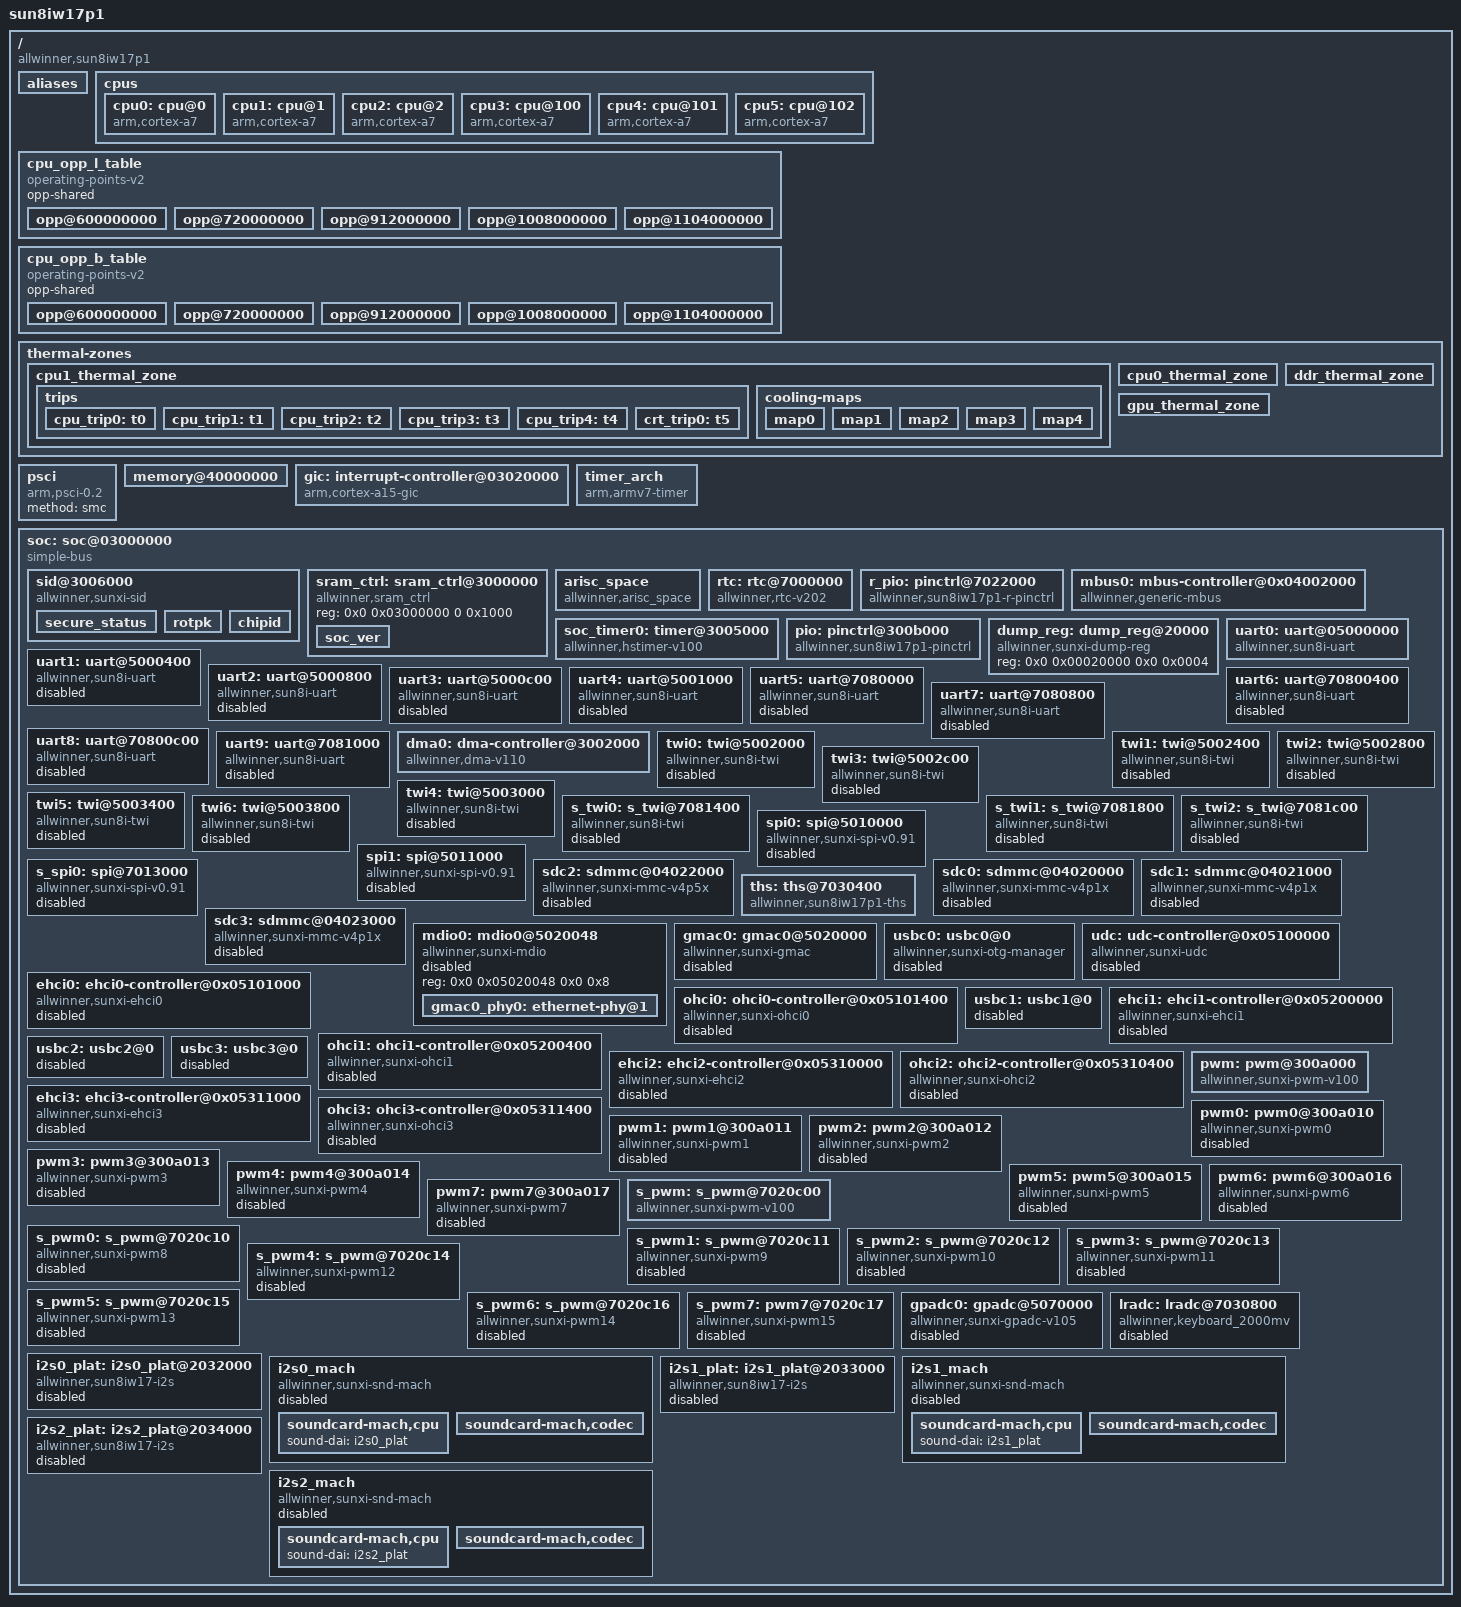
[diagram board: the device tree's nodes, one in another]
/* SPDX-License-Identifier: GPL-2.0-or-later */
/*
 * Allwinner Technology CO., Ltd. sun8iw17p1 platform
 *
 * modify base on juno.dts
 */

/* nobody use, just to "avoid"(not reslove) OOM problem at the begining of the physical memory address. */
/memreserve/ 0x40000000 0x00001000; /* reserve for out of memory access problem: size = 4K */

/* kernel used */
/memreserve/ 0x43000000 0x00000800; /* super standby range        : [0x40020000~0x41020800], size = 2K  */
/memreserve/ 0x48000000 0x01000000; /* atf                        : [0x48000000~0x49000000], size = 16M */

/* tf used */
/memreserve/ 0x48100000 0x00004000; /* arisc dram code space range: [0x48100000~0x48104000], size = 16K */
/memreserve/ 0x48104000 0x00001000; /* arisc para cfg range       : [0x48104000~0x48105000], size = 4K  */
/memreserve/ 0x48105000 0x00001000; /* arisc message pool range   : [0x48105000~0x48106000], size = 4K  */

/* pstore used */
/memreserve/ 0x48106000 0x00100000; /* ram oops log range   : [0x48106000~0x48206000], size = 1M  */
/memreserve/ 0x48200000 0x00100000; /* 360 config  size = 1M  */

#include <dt-bindings/interrupt-controller/arm-gic.h>
#include <dt-bindings/gpio/gpio.h>
#include "sun8iw17p1-clk.dtsi"
#include <dt-bindings/gpio/sun4i-gpio.h>
#include <dt-bindings/spi/sunxi-spi.h>
#include <dt-bindings/reset/sun8iw17-ccu.h>
#include <dt-bindings/reset/sun8iw17-r-ccu.h>
/ {
	model = "sun8iw17p1";
	compatible = "allwinner,sun8iw17p1";
	interrupt-parent = <&gic>;
	#address-cells = <2>;
	#size-cells = <2>;

	aliases {
		serial0 = &uart0;
		serial1 = &uart1;
		serial2 = &uart2;
		serial3 = &uart3;
		serial4 = &uart4;
		serial5 = &uart5;
		serial6 = &uart6;
		serial7 = &uart7;
		serial8 = &uart8;
		serial9 = &uart9;
		twi0 = &twi0;
		twi1 = &twi1;
		twi2 = &twi2;
		twi3 = &twi3;
		twi4 = &twi4;
		twi5 = &twi5;
		twi6 = &twi6;
		twi7 = &s_twi0;
		twi8 = &s_twi1;
		twi9 = &s_twi2;
		spi0 = &spi0;
		spi1 = &spi1;
		spi2 = &s_spi0;
		pwm0 = &pwm;
		pwm1 = &s_pwm;
		gpadc0 = &gpadc0;
	};

	cpus {
		#address-cells = <1>;
		#size-cells = <0>;

		cpu0: cpu@0 {
			device_type = "cpu";
			compatible = "arm,cortex-a7";
			reg = <0x0>;
			enable-method = "psci";
			clocks = <&clk_pll_cpu0>;
			clock-latency = <2000000>;
			clock-frequency = <1008000000>;
			operating-points-v2 = <&cpu_opp_l_table>;
			#cooling-cells = <2>;
		};

		cpu1: cpu@1 {
			device_type = "cpu";
			compatible = "arm,cortex-a7";
			reg = <0x1>;
			enable-method = "psci";
			clocks = <&clk_pll_cpu0>;
			clock-frequency = <1008000000>;
			operating-points-v2 = <&cpu_opp_l_table>;
			#cooling-cells = <2>;
		};

		cpu2: cpu@2 {
			device_type = "cpu";
			compatible = "arm,cortex-a7";
			reg = <0x2>;
			enable-method = "psci";
			clocks = <&clk_pll_cpu0>;
			clock-frequency = <1008000000>;
			operating-points-v2 = <&cpu_opp_l_table>;
			#cooling-cells = <2>;
		};

		cpu3: cpu@100 {
			device_type = "cpu";
			compatible = "arm,cortex-a7";
			reg = <0x100>;
			enable-method = "psci";
			clocks = <&clk_pll_cpu1>;
			clock-frequency = <1008000000>;
			operating-points-v2 = <&cpu_opp_b_table>;
			#cooling-cells = <2>;
		};

		cpu4: cpu@101 {
			device_type = "cpu";
			compatible = "arm,cortex-a7";
			reg = <0x101>;
			enable-method = "psci";
			clocks = <&clk_pll_cpu1>;
			clock-frequency = <1008000000>;
			operating-points-v2 = <&cpu_opp_b_table>;
			#cooling-cells = <2>;
		};

		cpu5: cpu@102 {
			device_type = "cpu";
			compatible = "arm,cortex-a7";
			reg = <0x102>;
			clocks = <&clk_pll_cpu1>;
			enable-method = "psci";
			clock-frequency = <1008000000>;
			operating-points-v2 = <&cpu_opp_b_table>;
			#cooling-cells = <2>;
		};
	};

	cpu_opp_l_table: cpu_opp_l_table {
		compatible = "operating-points-v2";
		opp-shared;

		opp@600000000 {
			opp-hz = /bits/ 64 <600000000>;
			opp-microvolt = <1060000>;
			clock-latency-ns = <2000000>;
		};

		opp@720000000 {
			opp-hz = /bits/ 64 <720000000>;
			opp-microvolt = <1060000>;
			clock-latency-ns = <2000000>;
		};

		opp@912000000 {
			opp-hz = /bits/ 64 <912000000>;
			opp-microvolt = <1200000>;
			clock-latency-ns = <2000000>;
		};

		opp@1008000000 {
			opp-hz = /bits/ 64 <1008000000>;
			opp-microvolt = <1260000>;
			clock-latency-ns = <2000000>;
		};

		opp@1104000000 {
			opp-hz = /bits/ 64 <1104000000>;
			opp-microvolt = <1300000>;
			clock-latency-ns = <2000000>;
		};
	};

	cpu_opp_b_table: cpu_opp_b_table {
		compatible = "operating-points-v2";
		opp-shared;

		opp@600000000 {
			opp-hz = /bits/ 64 <600000000>;
			opp-microvolt = <1060000>;
			clock-latency-ns = <2000000>;
		};

		opp@720000000 {
			opp-hz = /bits/ 64 <720000000>;
			opp-microvolt = <1060000>;
			clock-latency-ns = <2000000>;
		};

		opp@912000000 {
			opp-hz = /bits/ 64 <912000000>;
			opp-microvolt = <1200000>;
			clock-latency-ns = <2000000>;
		};

		opp@1008000000 {
			opp-hz = /bits/ 64 <1008000000>;
			opp-microvolt = <1260000>;
			clock-latency-ns = <2000000>;
		};

		opp@1104000000 {
			opp-hz = /bits/ 64 <1104000000>;
			opp-microvolt = <1300000>;
			clock-latency-ns = <2000000>;
		};
	};

	thermal-zones {
		cpu1_thermal_zone {
			polling-delay-passive = <1000>;
			polling-delay = <10000>;
			thermal-sensors = <&ths 0>;

			trips {
				cpu_trip0: t0 {
					temperature = <60000>;
					hysteresis = <0>;
					type = "passive";
				};

				cpu_trip1: t1 {
					temperature = <70000>;
					hysteresis = <0>;
					type = "passive";
				};

				cpu_trip2: t2 {
					temperature = <80000>;
					hysteresis = <0>;
					type = "passive";
				};

				cpu_trip3: t3 {
					temperature = <90000>;
					hysteresis = <0>;
					type = "passive";
				};

				cpu_trip4: t4 {
					temperature = <100000>;
					hysteresis = <0>;
					type = "passive";
				};

				crt_trip0: t5 {
					temperature = <120000>;
					hysteresis = <0>;
					type = "critical";
				};
			};

			cooling-maps {
				map0 {
					trip = <&cpu_trip0>;
					cooling-device = <&cpu0 1 1>,
							 <&cpu1 1 1>,
							 <&cpu2 1 1>,
							 <&cpu3 1 1>,
							 <&cpu4 1 1>,
							 <&cpu5 1 1>;
				};

				map1 {
					trip = <&cpu_trip1>;
					cooling-device = <&cpu0 2 2>,
							 <&cpu1 2 2>,
							 <&cpu2 2 2>,
							 <&cpu3 2 2>,
							 <&cpu4 2 2>,
							 <&cpu5 2 2>;
				};

				map2 {
					trip = <&cpu_trip2>;
					cooling-device = <&cpu0 3 3>,
							 <&cpu1 3 3>,
							 <&cpu2 3 3>,
							 <&cpu3 3 3>,
							 <&cpu4 3 3>,
							 <&cpu5 3 3>;
				};

				map3 {
					trip = <&cpu_trip3>;
					cooling-device = <&cpu0 4 4>,
							 <&cpu1 4 4>,
							 <&cpu2 4 4>,
							 <&cpu3 4 4>,
							 <&cpu4 4 4>,
							 <&cpu5 4 4>;
				};

				map4 {
					trip = <&cpu_trip4>;
					cooling-device = <&cpu0 5 5>,
							 <&cpu1 5 5>,
							 <&cpu2 5 5>,
							 <&cpu3 5 5>,
							 <&cpu4 5 5>,
							 <&cpu5 5 5>;
				};
			};
		};

		cpu0_thermal_zone {
			polling-delay-passive = <1000>;
			polling-delay = <10000>;
			thermal-sensors = <&ths 1>;
		};

		ddr_thermal_zone {
			polling-delay-passive = <1000>;
			polling-delay = <10000>;
			thermal-sensors = <&ths 2>;
		};

		gpu_thermal_zone {
			polling-delay-passive = <1000>;
			polling-delay = <10000>;
			thermal-sensors = <&ths 3>;
		};
	};

	psci {
		compatible = "arm,psci-0.2";
		method = "smc";
	};

	memory@40000000 {
		device_type = "memory";
		reg = <0x00000000 0x40000000 0x00000000 0x20000000>;
	};

	gic: interrupt-controller@03020000 {
		compatible = "arm,cortex-a15-gic", "arm,cortex-a9-gic";
		#interrupt-cells = <3>;
		#address-cells = <0>;
		device_type = "gic";
		interrupt-controller;
		reg = <0x0 0x03021000 0 0x1000>, /* GIC Dist */
		      <0x0 0x03022000 0 0x2000>, /* GIC CPU */
		      <0x0 0x03024000 0 0x2000>, /* GIC VCPU Control */
		      <0x0 0x03026000 0 0x2000>; /* GIC VCPU */
		interrupts = <GIC_PPI 9 0xf04>; /* GIC Maintenence IRQ */
	};

	timer_arch {
		compatible = "arm,armv7-timer";
		interrupts = <GIC_PPI 13 (GIC_CPU_MASK_SIMPLE(6) | IRQ_TYPE_LEVEL_LOW)>, /* Secure Phys IRQ */
			     <GIC_PPI 14 (GIC_CPU_MASK_SIMPLE(6) | IRQ_TYPE_LEVEL_LOW)>; /* Non-secure Phys IRQ */
		clock-frequency = <24000000>;
		arm,cpu-registers-not-fw-configured;
		arm,no-tick-in-suspend;
	};

	soc: soc@03000000 {
		compatible = "simple-bus";
		#address-cells = <2>;
		#size-cells = <2>;
		ranges;
		device_type = "soc";

		sid@3006000 {
			compatible = "allwinner,sunxi-sid";
			reg = <0x0 0x03006000 0 0x1000>;
			#address-cells = <1>;
			#size-cells = <1>;
			non-secure-maxoffset = <0x40>;
			non-secure-maxlen = <0x16>;

			secure_status {
				offset = <0xa0>;
				size = <0x4>;
			};
			rotpk {
				offset = <0x140>;
				size = <0x4>;
			};
			chipid {
				offset = <0x200>;
				size = <0x10>;
			};
		};

		sram_ctrl: sram_ctrl@3000000 {
			compatible = "allwinner,sram_ctrl";
			reg = <0x0 0x03000000 0 0x1000>;
			soc_ver {
				offset = <0x24>;
				mask = <0x7>;
				shift = <0>;
			};
		};

		arisc_space {
			compatible = "allwinner,arisc_space";
			/* num    dst        offset     size                              */
			space1 = <0x48040000 0x00000000 0x00014000>; /* srama2 code space */
			space2 = <0x48100000 0x00018000 0x00004000>; /* dram code space   */
			space3 = <0x48104000 0x00000000 0x00001000>; /* para space        */
			space4 = <0x48105000 0x00000000 0x00001000>; /* msgpool space     */
		};

		rtc: rtc@7000000 {
			compatible = "allwinner,rtc-v202";
			device_type = "rtc";
			wakeup-source;
			auto_switch;
			reg = <0x0 0x07000000 0x0 0x320>;
			interrupts = <GIC_SPI 133 IRQ_TYPE_LEVEL_HIGH>;
			clocks = <&clk_cpurrtc>;
			clock-names = "r-ahb-rtc";
			gpr_cur_pos = <6>;
			gpr_bootcount_pos = <7>;
		};

		r_pio: pinctrl@7022000 {
			compatible = "allwinner,sun8iw17p1-r-pinctrl";
			reg = <0x0 0x07022000 0x0 0x400>;
			interrupts = <GIC_SPI 138 IRQ_TYPE_LEVEL_HIGH>,
				     <GIC_SPI 139 IRQ_TYPE_LEVEL_HIGH>;
			clocks = <&clk_cpurpio>;
			gpio-controller;
			interrupt-controller;
			#interrupt-cells = <3>;
			#size-cells = <0>;
			#gpio-cells = <3>;
		};

		mbus0: mbus-controller@0x04002000 {
			compatible = "allwinner,generic-mbus";
			reg = <0x0 0x04002000 0x0 0x1000>;
			#mbus-cells = <1>;
			status = "okay";
			master_pmu_names = "pmu_cpuddr", "pmu_gpu_ddr", "pmu_ve_ddr",
			"pmu_csi_ddr", "pmu_othddr", "pmu_totddr";
			master_pmu_idxs = <0 1 2 6 4 5>;
			master_port_idxs = <0 1 4 11>;
		};

		soc_timer0: timer@3005000 {
			compatible = "allwinner,hstimer-v100";
			device_type = "soc_timer";
			reg = <0x0 0x03005000 0x0 0x100>;
			interrupts = <GIC_SPI 67 IRQ_TYPE_LEVEL_HIGH>;
			clocks = <&clk_hosc>, <&clk_hstimer>;
			clock-names = "parent", "bus";
			resets = <&ccu RST_HSTIMER_BGR>;
		};

		pio: pinctrl@300b000 {
			compatible = "allwinner,sun8iw17p1-pinctrl";
			reg = <0x0 0x0300b000 0x0 0x400>;
			interrupts = <GIC_SPI 84 IRQ_TYPE_LEVEL_HIGH>,
				     <GIC_SPI 85 IRQ_TYPE_LEVEL_HIGH>,
				     <GIC_SPI 86 IRQ_TYPE_LEVEL_HIGH>,
				     <GIC_SPI 87 IRQ_TYPE_LEVEL_HIGH>,
				     <GIC_SPI 88 IRQ_TYPE_LEVEL_HIGH>;
			clocks = <&clk_pio>;
			gpio-controller;
			interrupt-controller;
			#interrupt-cells = <3>;
			#size-cells = <0>;
			#gpio-cells = <3>;
		};

		dump_reg: dump_reg@20000 {
			compatible = "allwinner,sunxi-dump-reg";
			reg = <0x0 0x00020000 0x0 0x0004>;
		};

		uart0: uart@05000000 {
			compatible = "allwinner,sun8i-uart";
			device_type = "uart0";
			reg = <0x0 0x05000000 0x0 0x400>;
			interrupts = <GIC_SPI 60 IRQ_TYPE_LEVEL_HIGH>;
			clocks = <&clk_uart0>;
			uart0_port = <0>;
			uart0_type = <2>;
			status = "okay";
		};

		uart1: uart@5000400 {
			compatible = "allwinner,sun8i-uart";
			device_type = "uart1";
			reg = <0x0 0x05000400 0x0 0x400>;
			interrupts = <GIC_SPI 61 IRQ_TYPE_LEVEL_HIGH>;
			clocks = <&clk_uart1>;
			sunxi,uart-fifosize = <256>;
			uart1_port = <1>;
			uart1_type = <4>;
			status = "disabled";
		};

		uart2: uart@5000800 {
			compatible = "allwinner,sun8i-uart";
			device_type = "uart2";
			reg = <0x0 0x05000800 0x0 0x400>;
			interrupts = <GIC_SPI 62 IRQ_TYPE_LEVEL_HIGH>;
			clocks = <&clk_uart2>;
			sunxi,uart-fifosize = <256>;
			uart2_port = <2>;
			uart2_type = <4>;
			status = "disabled";
		};

		uart3: uart@5000c00 {
			compatible = "allwinner,sun8i-uart";
			device_type = "uart3";
			reg = <0x0 0x05000c00 0x0 0x400>;
			interrupts = <GIC_SPI 63 IRQ_TYPE_LEVEL_HIGH>;
			clocks = <&clk_uart3>;
			sunxi,uart-fifosize = <256>;
			uart3_port = <3>;
			uart3_type = <4>;
			status = "disabled";
		};

		uart4: uart@5001000 {
			compatible = "allwinner,sun8i-uart";
			device_type = "uart4";
			reg = <0x0 0x05001000 0x0 0x400>;
			interrupts = <GIC_SPI 64 IRQ_TYPE_LEVEL_HIGH>;
			clocks = <&clk_uart4>;
			sunxi,uart-fifosize = <256>;
			uart4_port = <4>;
			uart4_type = <4>;
			status = "disabled";
		};

		uart5: uart@7080000 {
			compatible = "allwinner,sun8i-uart";
			device_type = "uart5";
			reg = <0x0 0x07080000 0x0 0x400>;
			interrupts = <GIC_SPI 141 IRQ_TYPE_LEVEL_HIGH>;
			clocks = <&clk_cpuruart0>;
			sunxi,uart-fifosize = <256>;
			uart5_port = <5>;
			uart5_type = <2>;
			status = "disabled";
		};

		uart6: uart@70800400 {
			compatible = "allwinner,sun8i-uart";
			device_type = "uart6";
			reg = <0x0 0x07080400 0x0 0x400>;
			interrupts = <GIC_SPI 142 IRQ_TYPE_LEVEL_HIGH>;
			clocks = <&clk_cpuruart1>;
			sunxi,uart-fifosize = <256>;
			uart6_port = <6>;
			uart6_type = <4>;
			status = "disabled";
		};

		uart7: uart@7080800 {
			compatible = "allwinner,sun8i-uart";
			device_type = "uart7";
			reg = <0x0 0x07080800 0x0 0x400>;
			interrupts = <GIC_SPI 143 IRQ_TYPE_LEVEL_HIGH>;
			clocks = <&clk_cpuruart2>;
			sunxi,uart-fifosize = <256>;
			uart7_port = <7>;
			uart7_type = <4>;
			status = "disabled";
		};

		uart8: uart@70800c00 {
			compatible = "allwinner,sun8i-uart";
			device_type = "uart8";
			reg = <0x0 0x07080c00 0x0 0x400>;
			interrupts = <GIC_SPI 144 IRQ_TYPE_LEVEL_HIGH>;
			clocks = <&clk_cpuruart3>;
			sunxi,uart-fifosize = <256>;
			uart8_port = <8>;
			uart8_type = <4>;
			status = "disabled";
		};

		uart9: uart@7081000 {
			compatible = "allwinner,sun8i-uart";
			device_type = "uart9";
			reg = <0x0 0x07081000 0x0 0x400>;
			interrupts = <GIC_SPI 145 IRQ_TYPE_LEVEL_HIGH>;
			clocks = <&clk_cpuruart4>;
			sunxi,uart-fifosize = <256>;
			uart9_port = <9>;
			uart9_type = <4>;
			status = "disabled";
		};

		dma0: dma-controller@3002000 {
			compatible = "allwinner,dma-v110";
			reg = <0x0 0x3002000 0x0 0x1000>;
			interrupts = <GIC_SPI 10 IRQ_TYPE_LEVEL_HIGH>;
			clocks = <&clk_dma>;
			clock-names = "bus";
			dma-channels = <12>;
			dma-requests = <64>;
			#dma-cells = <1>;
		};

		twi0: twi@5002000 {
			#address-cells = <1>;
			#size-cells = <0>;
			compatible = "allwinner,sun8i-twi";
			device_type = "twi0";
			reg = <0x0 0x05002000 0x0 0x400>;
			interrupts = <GIC_SPI 46 IRQ_TYPE_LEVEL_HIGH>;
			clocks = <&clk_twi0>;
			twi_drv_used = <0>; /* only support eng mode for this platform */
			status = "disabled";
		};

		twi1: twi@5002400 {
			#address-cells = <1>;
			#size-cells = <0>;
			compatible = "allwinner,sun8i-twi";
			device_type = "twi1";
			reg = <0x0 0x05002400 0x0 0x400>;
			interrupts = <GIC_SPI 47 IRQ_TYPE_LEVEL_HIGH>;
			clocks = <&clk_twi1>;
			twi_drv_used = <0>; /* only support eng mode for this platform */
			status = "disabled";
		};

		twi2: twi@5002800 {
			#address-cells = <1>;
			#size-cells = <0>;
			compatible = "allwinner,sun8i-twi";
			device_type = "twi2";
			reg = <0x0 0x05002800 0x0 0x400>;
			interrupts = <GIC_SPI 48 IRQ_TYPE_LEVEL_HIGH>;
			clocks = <&clk_twi2>;
			twi_drv_used = <0>; /* only support eng mode for this platform */
			status = "disabled";
		};

		twi3: twi@5002c00 {
			#address-cells = <1>;
			#size-cells = <0>;
			compatible = "allwinner,sun8i-twi";
			device_type = "twi3";
			reg = <0x0 0x05002c00 0x0 0x400>;
			interrupts = <GIC_SPI 49 IRQ_TYPE_LEVEL_HIGH>;
			clocks = <&clk_twi3>;
			twi_drv_used = <0>; /* only support eng mode for this platform */
			status = "disabled";
		};

		twi4: twi@5003000 {
			#address-cells = <1>;
			#size-cells = <0>;
			compatible = "allwinner,sun8i-twi";
			device_type = "twi4";
			reg = <0x0 0x05003000 0x0 0x400>;
			interrupts = <GIC_SPI 50 IRQ_TYPE_LEVEL_HIGH>;
			clocks = <&clk_twi4>;
			twi_drv_used = <0>; /* only support eng mode for this platform */
			status = "disabled";
		};

		twi5: twi@5003400 {
			#address-cells = <1>;
			#size-cells = <0>;
			compatible = "allwinner,sun8i-twi";
			device_type = "twi5";
			reg = <0x0 0x05003400 0x0 0x400>;
			interrupts = <GIC_SPI 118 IRQ_TYPE_LEVEL_HIGH>;
			clocks = <&clk_twi5>;
			twi_drv_used = <0>; /* only support eng mode for this platform */
			status = "disabled";
		};

		twi6: twi@5003800 {
			#address-cells = <1>;
			#size-cells = <0>;
			compatible = "allwinner,sun8i-twi";
			device_type = "twi6";
			reg = <0x0 0x05003800 0x0 0x400>;
			interrupts = <GIC_SPI 119 IRQ_TYPE_LEVEL_HIGH>;
			clocks = <&clk_twi6>;
			twi_drv_used = <0>; /* only support eng mode for this platform */
			status = "disabled";
		};

		s_twi0: s_twi@7081400 {
			#address-cells = <1>;
			#size-cells = <0>;
			compatible = "allwinner,sun8i-twi";
			device_type = "s_twi0";
			reg = <0x0 0x07081400 0x0 0x400>;
			interrupts = <GIC_SPI 146 IRQ_TYPE_LEVEL_HIGH>;
			clocks = <&clk_cpurtwi0>;
			twi_drv_used = <0>; /* only support eng mode for this platform */
			status = "disabled";
		};

		s_twi1: s_twi@7081800 {
			#address-cells = <1>;
			#size-cells = <0>;
			compatible = "allwinner,sun8i-twi";
			device_type = "s_twi1";
			reg = <0x0 0x07081800 0x0 0x400>;
			interrupts = <GIC_SPI 147 IRQ_TYPE_LEVEL_HIGH>;
			clocks = <&clk_cpurtwi1>;
			twi_drv_used = <0>; /* only support eng mode for this platform */
			status = "disabled";
		};

		s_twi2: s_twi@7081c00 {
			#address-cells = <1>;
			#size-cells = <0>;
			compatible = "allwinner,sun8i-twi";
			device_type = "s_twi2";
			reg = <0x0 0x07081c00 0x0 0x400>;
			interrupts = <GIC_SPI 148 IRQ_TYPE_LEVEL_HIGH>;
			clocks = <&clk_cpurtwi2>;
			twi_drv_used = <0>; /* only support eng mode for this platform */
			status = "disabled";
		};

		spi0: spi@5010000 {
			#address-cells = <1>;
			#size-cells = <0>;
			compatible = "allwinner,sunxi-spi-v0.91";
			device_type = "spi0";
			reg = <0x0 0x05010000 0x0 0x1000>;
			interrupts = <GIC_SPI 65 IRQ_TYPE_LEVEL_HIGH>;
			clocks = <&clk_pll_periph0>, <&clk_spi0>;
			clock-frequency = <100000000>;
			sunxi,spi-num-cs = <1>;
			status = "disabled";
		};

		spi1: spi@5011000 {
			#address-cells = <1>;
			#size-cells = <0>;
			compatible = "allwinner,sunxi-spi-v0.91";
			device_type = "spi1";
			reg = <0x0 0x05011000 0x0 0x1000>;
			interrupts = <GIC_SPI 66 IRQ_TYPE_LEVEL_HIGH>;
			clocks = <&clk_pll_periph0>, <&clk_spi1>;
			clock-frequency = <100000000>;
			sunxi,spi-num-cs = <1>;
			status = "disabled";
		};

		s_spi0: spi@7013000 {
			#address-cells = <1>;
			#size-cells = <0>;
			compatible = "allwinner,sunxi-spi-v0.91";
			device_type = "s_spi0";
			reg = <0x0 0x07013000 0x0 0x1000>;
			interrupts = <GIC_SPI 155 IRQ_TYPE_LEVEL_HIGH>;
			clocks = <&clk_pll_periph0>, <&clk_cpurspi>;
			clock-frequency = <100000000>;
			sunxi,spi-num-cs = <1>;
			status = "disabled";
		};

		sdc2: sdmmc@04022000 {
			compatible = "allwinner,sunxi-mmc-v4p5x";
			device_type = "sdc2";
			reg = <0x0 0x04022000 0x0 0x1000>;
			interrupts = <GIC_SPI 54 0x0104>;
			clocks = <&clk_hosc>,
				 <&clk_pll_periph1x2>,
				 <&clk_sdmmc2_mod>,
				 <&clk_sdmmc2_bus>,
				 <&clk_sdmmc2_rst>;
			clock-names = "osc24m","pll_periph","mmc","ahb","rst";
			pinctrl-names = "default","sleep";
			pinctrl-0 = <&sdc2_pins_a>;
			pinctrl-1 = <&sdc2_pins_b>;
			bus-width = <8>;
			cap-mmc-highspeed;
			cap-cmd23;
			/*mmc-ddr-1_8v;*/
			/*mmc-hs200-1_8v;*/
			/*mmc-hs400-1_8v;*/
			non-removable;
			/*max-frequency = <200000000>;*/
			max-frequency = <50000000>;
			cap-erase;
			mmc-high-capacity-erase-size;
			no-sdio;
			no-sd;
			/*-- speed mode --*/
			/*sm0: DS26_SDR12*/
			/*sm1: HSSDR52_SDR25*/
			/*sm2: HSDDR52_DDR50*/
			/*sm3: HS200_SDR104*/
			/*sm4: HS400*/
			/*-- frequency point --*/
			/*f0: CLK_400K*/
			/*f1: CLK_25M*/
			/*f2: CLK_50M*/
			/*f3: CLK_100M*/
			/*f4: CLK_150M*/
			/*f5: CLK_200M*/

			sdc_tm4_sm0_freq0 = <0>;
			sdc_tm4_sm0_freq1 = <0>;
			sdc_tm4_sm1_freq0 = <0x00000000>;
			sdc_tm4_sm1_freq1 = <0>;
			sdc_tm4_sm2_freq0 = <0x00000000>;
			sdc_tm4_sm2_freq1 = <0>;
			sdc_tm4_sm3_freq0 = <0x05000000>;
			sdc_tm4_sm3_freq1 = <0x00000005>;
			sdc_tm4_sm4_freq0 = <0x00050000>;
			sdc_tm4_sm4_freq1 = <0x00000004>;

			/*vmmc-supply = <&reg_3p3v>;*/
			/*vqmc-supply = <&reg_3p3v>;*/
			/*vdmc-supply = <&reg_3p3v>;*/
			/*vmmc = "vcc-card";*/
			/*vqmc = "";*/
			/*vdmc = "";*/
			/*sunxi-power-save-mode;*/
			/*status = "disabled";*/
			ctl-spec-caps = <0x308>;
			status = "disabled";
		};

		sdc0: sdmmc@04020000 {
			compatible = "allwinner,sunxi-mmc-v4p1x";
			device_type = "sdc0";
			reg = <0x0 0x04020000 0x0 0x1000>;
			interrupts = <GIC_SPI 52 0x0104>;
			clocks = <&clk_hosc>,
				 <&clk_pll_periph1x2>,
				 <&clk_sdmmc0_mod>,
				 <&clk_sdmmc0_bus>,
				 <&clk_sdmmc0_rst>;
			clock-names = "osc24m","pll_periph","mmc","ahb","rst";
			pinctrl-names = "default","sleep";
			pinctrl-0 = <&sdc0_pins_a>;
			pinctrl-1 = <&sdc0_pins_b>;
			max-frequency = <50000000>;
			bus-width = <4>;
			/*non-removable;*/
			/*broken-cd;*/
			/*cd-inverted*/
			cd-gpios = <&pio PF 6 0 1 2 0>;
			/* vmmc-supply = <&reg_3p3v>;*/
			/* vqmc-supply = <&reg_3p3v>;*/
			/* vdmc-supply = <&reg_3p3v>;*/
			/*vmmc = "vcc-card";*/
			/*vqmc = "";*/
			/*vdmc = "";*/
			cap-sd-highspeed;
			no-sdio;
			no-mmc;
			/*sd-uhs-sdr50;*/
			/*sd-uhs-ddr50;*/
			/*cap-sdio-irq;*/
			/*keep-power-in-suspend;*/
			/*ignore-pm-notify;*/
			/*sunxi-power-save-mode;*/
			/*sunxi-dly-400k = <1 0 0 0>; */
			/*sunxi-dly-26M  = <1 0 0 0>;*/
			/*sunxi-dly-52M  = <1 0 0 0>;*/
			/*sunxi-dly-52M-ddr4  = <1 0 0 0>;*/
			/*sunxi-dly-52M-ddr8  = <1 0 0 0>;*/
			/*sunxi-dly-104M  = <1 0 0 0>;*/
			/*sunxi-dly-208M  = <1 0 0 0>;*/
			/*sunxi-dly-104M-ddr  = <1 0 0 0>;*/
			/*sunxi-dly-208M-ddr  = <1 0 0 0>;*/

			status = "disabled";
		};

		sdc1: sdmmc@04021000 {
			compatible = "allwinner,sunxi-mmc-v4p1x";
			device_type = "sdc1";
			reg = <0x0 0x04021000 0x0 0x1000>;
			interrupts = <GIC_SPI 53 0x0104>;
			clocks = <&clk_hosc>,
				 <&clk_pll_periph1x2>,
				 <&clk_sdmmc1_mod>,
				 <&clk_sdmmc1_bus>,
				 <&clk_sdmmc1_rst>;
			clock-names = "osc24m","pll_periph","mmc","ahb","rst";
			pinctrl-names = "default","sleep";
			pinctrl-0 = <&sdc1_pins_a>;
			pinctrl-1 = <&sdc1_pins_b>;
			max-frequency = <50000000>;
			bus-width = <4>;
			/*broken-cd;*/
			/*cd-inverted*/
			/*cd-gpios = <&pio PG 6 6 1 2 0>;*/
			/* vmmc-supply = <&reg_3p3v>;*/
			/* vqmc-supply = <&reg_3p3v>;*/
			/* vdmc-supply = <&reg_3p3v>;*/
			/*vmmc = "vcc-card";*/
			/*vqmc = "";*/
			/*vdmc = "";*/
			cap-sd-highspeed;
			no-mmc;
			/*sd-uhs-sdr50;*/
			/*sd-uhs-ddr50;*/
			/*sd-uhs-sdr104;*/
			/*cap-sdio-irq;*/
			/*keep-power-in-suspend;*/
			/*ignore-pm-notify;*/
			/*sunxi-power-save-mode;*/
			/*sunxi-dly-400k = <1 0 0 0 0>; */
			/*sunxi-dly-26M  = <1 0 0 0 0>;*/
			/*sunxi-dly-52M  = <1 0 0 0 0>;*/
			sunxi-dly-52M  = <1 1 0 0 1>;
			sunxi-dly-52M-ddr4  = <1 0 0 0 2>;
			/*sunxi-dly-52M-ddr8  = <1 0 0 0 0>;*/
			sunxi-dly-104M  = <1 0 0 0 1>;
			/*sunxi-dly-208M  = <1 1 0 0 0>;*/
			sunxi-dly-208M  = <1 0 0 0 1>;
			/*sunxi-dly-104M-ddr  = <1 0 0 0 0>;*/
			/*sunxi-dly-208M-ddr  = <1 0 0 0 0>;*/

			status = "disabled";
			/*status = "okay";*/
		};

		sdc3: sdmmc@04023000 {
			compatible = "allwinner,sunxi-mmc-v4p1x";
			device_type = "sdc3";
			reg = <0x0 0x04023000 0x0 0x1000>;
			interrupts = <GIC_SPI 55 0x0104>;
			clocks = <&clk_hosc>,
				 <&clk_pll_periph1x2>,
				 <&clk_sdmmc3_mod>,
				 <&clk_sdmmc3_bus>,
				 <&clk_sdmmc3_rst>;
			clock-names = "osc24m","pll_periph","mmc","ahb","rst";
			pinctrl-names = "default","sleep";
			pinctrl-0 = <&sdc3_pins_a>;
			pinctrl-1 = <&sdc3_pins_b>;
			max-frequency = <50000000>;
			bus-width = <4>;
			cap-sd-highspeed;
			no-sdio;
			no-mmc;

			/*broken-cd;*/
			/*cd-inverted*/
			/*cd-gpios = <&pio PG 6 6 1 2 0>;*/
			/* vmmc-supply = <&reg_3p3v>;*/
			/* vqmc-supply = <&reg_3p3v>;*/
			/* vdmc-supply = <&reg_3p3v>;*/
			/*vmmc = "vcc-card";*/
			/*vqmc = "";*/
			/*vdmc = "";*/
			/*sd-uhs-sdr50;*/
			/*sd-uhs-ddr50;*/
			/*sd-uhs-sdr104;*/
			/*cap-sdio-irq;*/
			/*keep-power-in-suspend;*/
			/*ignore-pm-notify;*/
			/*sunxi-power-save-mode;*/
			/*sunxi-dly-400k = <1 0 0 0 0>; */
			/*sunxi-dly-26M  = <1 0 0 0 0>;*/
			/*sunxi-dly-52M  = <1 0 0 0 0>;*/
			/*sunxi-dly-52M-ddr8  = <1 0 0 0 0>;*/
			/*sunxi-dly-208M  = <1 1 0 0 0>;*/
			/*sunxi-dly-104M-ddr  = <1 0 0 0 0>;*/
			/*sunxi-dly-208M-ddr  = <1 0 0 0 0>;*/

			status = "disabled";
			/*status = "okay";*/
		};

		ths: ths@7030400{
			compatible = "allwinner,sun8iw17p1-ths";
			reg = <0x0 0x07030400 0x0 0x400>;
			clocks = <&clk_cpurths>;
			clock-names = "bus";
			resets = <&r_ccu RST_R_THS>;
			#thermal-sensor-cells = <1>;
		};

		mdio0: mdio0@5020048 {
			compatible = "allwinner,sunxi-mdio";
			#address-cells = <1>;
			#size-cells = <0>;
			reg = <0x0 0x05020048 0x0 0x8>;
			status = "disabled";
			gmac0_phy0: ethernet-phy@1 {
				reg = <1>;
				max-speed = <100>;  /* Max speed capability */
				/* PHY datasheet rst time */
				reset-assert-us = <10000>;
				reset-deassert-us = <150000>;
			};
		};

		gmac0: gmac0@5020000 {
			compatible = "allwinner,sunxi-gmac";
			reg = <0x0 0x05020000 0x0 0x1000>,
				<0x0 0x03000030 0x0 0x4>;
			interrupts = <GIC_SPI 27 IRQ_TYPE_LEVEL_HIGH>;
			interrupt-names = "gmacirq";
			clocks = <&clk_gmac>;
			clock-names = "gmac";
			phy-handle = <&gmac0_phy0>;
			status = "disabled";
		};

		usbc0:usbc0@0 {
			device_type = "usbc0";
			compatible = "allwinner,sunxi-otg-manager";
			usb_port_type = <2>;
			usb_detect_type = <1>;
			usb_id_gpio;
			usb_det_vbus_gpio;
			usb_drv_vbus_gpio;
			usb_regulator_io = "nocare";
			usb_wakeup_suspend = <0>;
			usb_luns = <3>;
			usb_serial_unique = <0>;
			usb_serial_number = "20080411";
			rndis_wceis = <1>;
			status = "disabled";
		};

		udc:udc-controller@0x05100000 {
			compatible = "allwinner,sunxi-udc";
			reg = <0x0 0x05100000 0x0 0x1000>, /*udc base*/
			      <0x0 0x00000000 0x0 0x100>; /*sram base*/
			interrupts = <GIC_SPI 75 IRQ_TYPE_LEVEL_HIGH>;
			clocks = <&clk_usbphy0>, <&clk_usbotg>;
			status = "disabled";
		};

		ehci0:ehci0-controller@0x05101000 {
			compatible = "allwinner,sunxi-ehci0";
			reg = <0x0 0x05101000 0x0 0xFFF>, /*hci0 base*/
			      <0x0 0x00000000 0x0 0x100>, /*sram base*/
			      <0x0 0x05100000 0x0 0x1000>; /*otg base*/
			interrupts = <GIC_SPI 76 IRQ_TYPE_LEVEL_HIGH>;
			clocks = <&clk_usbphy0>, <&clk_usbehci0>;
			hci_ctrl_no = <0>;
			status = "disabled";
		};

		ohci0:ohci0-controller@0x05101400 {
			compatible = "allwinner,sunxi-ohci0";
			reg = <0x0 0x05101400 0x0 0xFFF>, /*hci0 base*/
			      <0x0 0x00000000 0x0 0x100>, /*sram base*/
			      <0x0 0x05100000 0x0 0x1000>; /*otg base*/
			interrupts = <GIC_SPI 77 IRQ_TYPE_LEVEL_HIGH>;
			clocks = <&clk_usbphy0>, <&clk_usbohci0>, <&clk_usbohci0_12m>, <&clk_osc48md4>, <&clk_hosc>, <&clk_losc>;
			hci_ctrl_no = <0>;
			status = "disabled";
		};

		usbc1:usbc1@0 {
			device_type         = "usbc1";
			usb_regulator_io    = "nocare";
			usb_wakeup_suspend  = <0>;
			status              = "disabled";
		};

		ehci1:ehci1-controller@0x05200000 {
			compatible = "allwinner,sunxi-ehci1";
			reg = <0x0 0x05200000 0x0 0xFFF>, /*hci1 base*/
			      <0x0 0x00000000 0x0 0x100>, /*sram base*/
			      <0x0 0x05100000 0x0 0x1000>; /*otg base*/
			interrupts = <GIC_SPI 78 IRQ_TYPE_LEVEL_HIGH>;
			clocks = <&clk_usbphy1>, <&clk_usbehci1>;
			hci_ctrl_no = <1>;
			status = "disabled";
		};

		ohci1:ohci1-controller@0x05200400 {
			compatible = "allwinner,sunxi-ohci1";
			reg = <0x0 0x05200400 0x0 0xFFF>, /*hci1 base*/
			      <0x0 0x00000000 0x0 0x100>, /*sram base*/
			      <0x0 0x05100000 0x0 0x1000>; /*otg base*/
			interrupts = <GIC_SPI 79 IRQ_TYPE_LEVEL_HIGH>;
			clocks = <&clk_usbphy1>, <&clk_usbohci1>, <&clk_usbohci1_12m>, <&clk_osc48md4>, <&clk_hosc>, <&clk_losc>;
			hci_ctrl_no = <1>;
			status = "disabled";
		};

		usbc2:usbc2@0 {
			device_type         = "usbc2";
			usb_regulator_io    = "nocare";
			usb_wakeup_suspend  = <0>;
			status              = "disabled";
		};

		ehci2:ehci2-controller@0x05310000 {
			compatible = "allwinner,sunxi-ehci2";
			reg = <0x0 0x05310000 0x0 0xFFF>, /*hci2 base*/
			      <0x0 0x00000000 0x0 0x100>, /*sram base*/
			      <0x0 0x05100000 0x0 0x1000>; /*otg base*/
			interrupts = <GIC_SPI 80 IRQ_TYPE_LEVEL_HIGH>;
			clocks = <&clk_usbphy2>, <&clk_usbehci2>;
			hci_ctrl_no = <2>;
			status = "disabled";
		};

		ohci2:ohci2-controller@0x05310400 {
			compatible = "allwinner,sunxi-ohci2";
			reg = <0x0 0x05310400 0x0 0xFFF>, /*hci2 base*/
			      <0x0 0x00000000 0x0 0x100>, /*sram base*/
			      <0x0 0x05100000 0x0 0x1000>; /*otg base*/
			interrupts = <GIC_SPI 81 IRQ_TYPE_LEVEL_HIGH>;
			clocks = <&clk_usbphy2>, <&clk_usbohci2>, <&clk_usbohci2_12m>, <&clk_osc48md4>, <&clk_hosc>, <&clk_losc>;
			hci_ctrl_no = <2>;
			status = "disabled";
		};

		usbc3:usbc3@0 {
			device_type         = "usbc3";
			usb_regulator_io    = "nocare";
			usb_wakeup_suspend  = <0>;
			status              = "disabled";
		};

		ehci3:ehci3-controller@0x05311000 {
			compatible = "allwinner,sunxi-ehci3";
			reg = <0x0 0x05311000 0x0 0xFFF>, /*hci3 base*/
			      <0x0 0x00000000 0x0 0x100>, /*sram base*/
			      <0x0 0x05100000 0x0 0x1000>; /*otg base*/
			interrupts = <GIC_SPI 82 IRQ_TYPE_LEVEL_HIGH>;
			clocks = <&clk_usbphy3>, <&clk_usbehci3>, <&clk_usbhsic>, <&clk_usbhsic12m>, <&clk_pll_hsic>;
			hci_ctrl_no = <3>;
			status = "disabled";
		};

		ohci3:ohci3-controller@0x05311400 {
			compatible = "allwinner,sunxi-ohci3";
			reg = <0x0 0x05311400 0x0 0xFFF>, /*hci3 base*/
			      <0x0 0x00000000 0x0 0x100>, /*sram base*/
			      <0x0 0x05100000 0x0 0x1000>; /*otg base*/
			interrupts = <GIC_SPI 83 IRQ_TYPE_LEVEL_HIGH>;
			clocks = <&clk_usbphy3>, <&clk_usbohci3>, <&clk_usbohci3_12m>, <&clk_osc48md4>, <&clk_hosc>, <&clk_losc>;
			hci_ctrl_no = <3>;
			status = "disabled";
		};

		pwm: pwm@300a000 {
			#pwm-cells = <0x3>;
			compatible = "allwinner,sunxi-pwm-v100";
			reg = <0x0 0x0300a000 0x0 0x400>;
			interrupts = <GIC_SPI 15 IRQ_TYPE_LEVEL_HIGH>;
			clocks = <&clk_pwm>;
			pwm-number = <8>;
			pwm-base = <0x0>;
			sunxi-pwms = <&pwm0>, <&pwm1>, <&pwm2>, <&pwm3>, <&pwm4>, <&pwm5>, <&pwm6>, <&pwm7>;
		};

		pwm0: pwm0@300a010 {
			compatible = "allwinner,sunxi-pwm0";
			reg = <0x0 0x0300a010 0x0 0x4>;
			reg_base = <0x0300a000>;
			status = "disabled";
		};

		pwm1: pwm1@300a011 {
			compatible = "allwinner,sunxi-pwm1";
			reg = <0x0 0x0300a011 0x0 0x4>;
			reg_base = <0x0300a000>;
			status = "disabled";
		};

		pwm2: pwm2@300a012 {
			compatible = "allwinner,sunxi-pwm2";
			reg = <0x0 0x0300a012 0x0 0x4>;
			reg_base = <0x0300a000>;
			status = "disabled";
		};

		pwm3: pwm3@300a013 {
			compatible = "allwinner,sunxi-pwm3";
			reg = <0x0 0x0300a013 0x0 0x4>;
			reg_base = <0x0300a000>;
			status = "disabled";
		};

		pwm4: pwm4@300a014 {
			compatible = "allwinner,sunxi-pwm4";
			reg = <0x0 0x0300a014 0x0 0x4>;
			reg_base = <0x0300a000>;
			status = "disabled";
		};

		pwm5: pwm5@300a015 {
			compatible = "allwinner,sunxi-pwm5";
			reg = <0x0 0x0300a015 0x0 0x4>;
			reg_base = <0x0300a000>;
			status = "disabled";
		};

		pwm6: pwm6@300a016 {
			compatible = "allwinner,sunxi-pwm6";
			reg = <0x0 0x0300a016 0x0 0x4>;
			reg_base = <0x0300a000>;
			status = "disabled";
		};

		pwm7: pwm7@300a017 {
			compatible = "allwinner,sunxi-pwm7";
			reg = <0x0 0x0300a017 0x0 0x4>;
			reg_base = <0x0300a000>;
			status = "disabled";
		};

		s_pwm: s_pwm@7020c00 {
			#pwm-cells = <0x3>;
			compatible = "allwinner,sunxi-pwm-v100";
			reg = <0x0 0x07020c00 0x0 0x400>;
			interrupts = <GIC_SPI 137 IRQ_TYPE_LEVEL_HIGH>;
			clocks = <&clk_pwm>;
			pwm-number = <8>;
			pwm-base = <0x9>;
			sunxi-pwms = <&s_pwm0>, <&s_pwm1>, <&s_pwm2>, <&s_pwm3>, <&s_pwm4>, <&s_pwm5>, <&s_pwm6>, <&s_pwm7>;
		};

		s_pwm0: s_pwm@7020c10 {
			compatible = "allwinner,sunxi-pwm8";
			reg = <0x0 0x07020c10 0x0 0x4>;
			reg_base = <0x07020c00>;
			status = "disabled";
		};

		s_pwm1: s_pwm@7020c11 {
			compatible = "allwinner,sunxi-pwm9";
			reg = <0x0 0x07020c11 0x0 0x4>;
			reg_base = <0x07020c00>;
			status = "disabled";
		};

		s_pwm2: s_pwm@7020c12 {
			compatible = "allwinner,sunxi-pwm10";
			reg = <0x0 0x07020c12 0x0 0x4>;
			reg_base = <0x07020c00>;
			status = "disabled";
		};

		s_pwm3: s_pwm@7020c13 {
			compatible = "allwinner,sunxi-pwm11";
			reg = <0x0 0x07020c13 0x0 0x4>;
			reg_base = <0x07020c00>;
			status = "disabled";
		};

		s_pwm4: s_pwm@7020c14 {
			compatible = "allwinner,sunxi-pwm12";
			reg = <0x0 0x07020c14 0x0 0x4>;
			reg_base = <0x07020c00>;
			status = "disabled";
		};

		s_pwm5: s_pwm@7020c15 {
			compatible = "allwinner,sunxi-pwm13";
			reg = <0x0 0x07020c15 0x0 0x4>;
			reg_base = <0x07020c00>;
			status = "disabled";
		};

		s_pwm6: s_pwm@7020c16 {
			compatible = "allwinner,sunxi-pwm14";
			reg = <0x0 0x07020c16 0x0 0x4>;
			reg_base = <0x07020c00>;
			status = "disabled";
		};

		s_pwm7: pwm7@7020c17 {
			compatible = "allwinner,sunxi-pwm15";
			reg = <0x0 0x07020c17 0x0 0x4>;
			reg_base = <0x07020c00>;
			status = "disabled";
		};

		gpadc0: gpadc@5070000 {
			compatible = "allwinner,sunxi-gpadc-v105";
			reg = <0x0 0x05070000 0x0 0x400>;
			interrupts = <GIC_SPI 0 IRQ_TYPE_LEVEL_HIGH>;
			clocks = <&clk_gpadc>;
			status = "disabled";
		};

		lradc: lradc@7030800 {
			compatible = "allwinner,keyboard_2000mv";
			reg = <0x0 0x07030800 0x0 0x400>;
			interrupts = <GIC_SPI 140 IRQ_TYPE_LEVEL_HIGH>;
			clocks = <&clk_cpurlradc>;
			status = "disabled";
		};

		/* audio dirver module -> I2S/PCM */
		i2s0_plat:i2s0_plat@2032000 {
			#sound-dai-cells = <0>;
			compatible = "allwinner,sun8iw17-i2s";
			reg		= <0x0 0x05090000 0x0 0x74>;
			resets		= <&ccu RST_I2S_PCM_0>;
			clocks		= <&clk_pll_audio>, <&clk_i2s0>;
			clock-names	= "clk_pll_audio", "clk_i2s";
			dmas		= <&dma0 3>, <&dma0 3>;
			dma-names	= "tx", "rx";
			playback-cma	= <128>;
			capture-cma	= <128>;
			tx-fifo-size	= <128>;
			rx-fifo-size	= <128>;
			status = "disabled";
		};

		i2s0_mach:i2s0_mach{
			compatible = "allwinner,sunxi-snd-mach";
			soundcard-mach,name		= "sndi2s0";
			soundcard-mach,format		= "i2s";
			soundcard-mach,slot-num		= <2>;
			soundcard-mach,slot-width	= <32>;
			status = "disabled";
			soundcard-mach,cpu {
				sound-dai = <&i2s0_plat>;
			};
			soundcard-mach,codec {
			};
		};

		i2s1_plat:i2s1_plat@2033000 {
			#sound-dai-cells = <0>;
			compatible = "allwinner,sun8iw17-i2s";
			reg		= <0x0 0x05091000 0x0 0x74>;
			resets		= <&ccu RST_I2S_PCM_1>;
			clocks		= <&clk_pll_audio>, <&clk_i2s1>;
			clock-names	= "clk_pll_audio", "clk_i2s";
			dmas		= <&dma0 4>, <&dma0 4>;
			dma-names	= "tx", "rx";
			playback-cma	= <128>;
			capture-cma	= <128>;
			tx-fifo-size	= <128>;
			rx-fifo-size	= <128>;
			status = "disabled";
		};

		i2s1_mach:i2s1_mach{
			compatible = "allwinner,sunxi-snd-mach";
			soundcard-mach,name		= "sndi2s1";
			soundcard-mach,format		= "i2s";
			soundcard-mach,slot-num		= <2>;
			soundcard-mach,slot-width	= <32>;
			status = "disabled";
			soundcard-mach,cpu {
				sound-dai = <&i2s1_plat>;
			};
			soundcard-mach,codec {
			};
		};

		i2s2_plat:i2s2_plat@2034000 {
			#sound-dai-cells = <0>;
			compatible = "allwinner,sun8iw17-i2s";
			reg		= <0x0 0x05092000 0x0 0x74>;
			resets		= <&ccu RST_I2S_PCM_2>;
			clocks		= <&clk_pll_audio>, <&clk_i2s2>;
			clock-names	= "clk_pll_audio", "clk_i2s";
			dmas		= <&dma0 5>, <&dma0 5>;
			dma-names	= "tx", "rx";
			playback-cma	= <128>;
			capture-cma	= <128>;
			tx-fifo-size	= <128>;
			rx-fifo-size	= <128>;
			status = "disabled";
		};

		i2s2_mach:i2s2_mach{
			compatible = "allwinner,sunxi-snd-mach";
			soundcard-mach,name		= "sndi2s2";
			soundcard-mach,format		= "i2s";
			soundcard-mach,slot-num		= <2>;
			soundcard-mach,slot-width	= <32>;
			status = "disabled";
			soundcard-mach,cpu {
				sound-dai = <&i2s2_plat>;
			};
			soundcard-mach,codec {
			};
		};
	};
};
